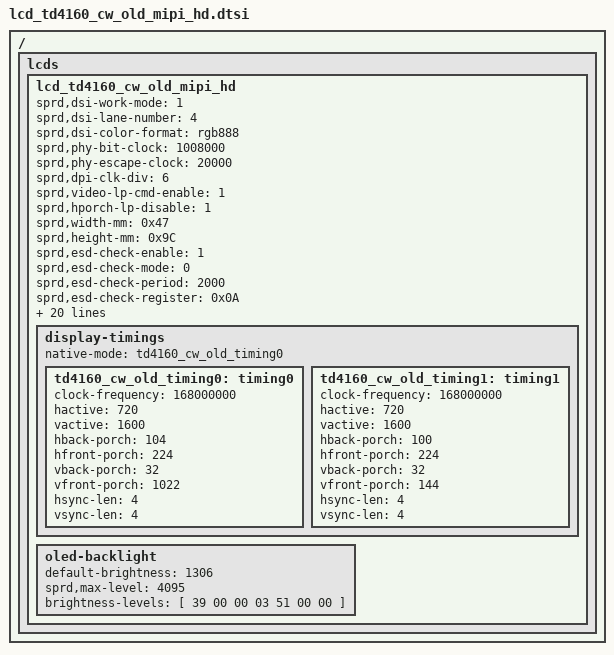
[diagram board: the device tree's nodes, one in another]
/*
 * R61350 Truly LCD config dtsi file for spreadtrum
 *
 * Copyright (C) 2018, Spreadtrum Communications Inc.
 *
 * SPDX-License-Identifier: (GPL-2.0+ OR MIT)
 */

/ {
	fragment {
		target-path = "/";
		__overlay__ {
			lcds {
				lcd_td4160_cw_old_mipi_hd: lcd_td4160_cw_old_mipi_hd {

					sprd,dsi-work-mode = <1>; /* video burst mode*/
					sprd,dsi-lane-number = <4>;
					sprd,dsi-color-format = "rgb888";

					sprd,phy-bit-clock = <1008000>;	/* kbps */
					sprd,phy-escape-clock = <20000>;/* kHz */
					sprd,dpi-clk-div = <6>;
					sprd,video-lp-cmd-enable = <1>;
					sprd,hporch-lp-disable = <1>;

					sprd,width-mm = <0x47>;
					sprd,height-mm = <0x9C>;

					sprd,esd-check-enable = <1>;
					sprd,esd-check-mode = <0>;
					sprd,esd-check-period = <2000>;
					sprd,esd-check-register = <0x0A>;
					sprd,esd-check-value = <0x9C>;

					sprd,power-i2c-bus = <4>;
					sprd,power-i2c-addr = <0x3e>;
					sprd,power-i2c-reg = [00 01 03];
					sprd,power-i2c-val = [14 14 43];

					sprd,reset-on-sequence = <1 5>, <0 5>, <1 30>;
					sprd,reset-off-sequence = <0 5>;

					/*
					 * Use 4 bits number for descripting video lp mode, and it can be combined used.
					 * BIT(0): allow vactive enter lp;
					 * BIT(1): allow vfp enter lp;
					 * BIT(2): allow vbp enter lp;
					 * BIT(3): allow vsa enter lp;
					 * For example:
					 * If we need vfp & vbp enter lp, we can calculate this value as a result of BIT(1) | BIT(2)
					 * And we get the result of 3 and set this value to lcd dt property sprd,video-lp-en-mode.
					 * If we need all stage can enter lp, we can calculate this value as a result of BIT(0) | BIT(1) | BIT(2) | BIT(3).
					 * And we get the result of 15 and set this value to lcd dt property sprd,video-lp-en-mode.
					 */
					sprd,video-lp-en-mode = <2>;
					sprd,use-dcs-write;
					sprd,initial-command = [
						39 00 00 02 B0 04
						39 00 00 02 D6 00
						39 00 00 07 B6 30 6A 00 86 C3 03
						39 00 00 05 B7 31 00 00 00
						39 00 00 07 B8 02 50 09 00 04 40
						39 00 00 07 B9 02 09 18 00 09 46
						39 00 00 07 BA 02 90 00 00 00 00
						39 00 00 04 BB 00 B4 A0
						39 00 00 04 BC 00 B4 A0
						39 00 00 04 BD 00 B4 A0
						39 00 00 0E BE 07 00 00 00 00 00 00 00 00 00 00 00 00
						39 00 00 19 C0 00 60 24 06 40 00 16 06 98 00 70 00 00 00 00 00 00 00 00 00 00 00 00 00
						39 00 00 28 C1 30 81 50 FA 01 00 00 10 00 00 00 00 40 0F 00 00 00 00 00 00 00 00 00 00 00 00 00 00 00 00 00 00 F0 07 08 07 D0 0A BE
						39 00 00 65 C2 01 20 50 14 04 10 0B 10 00 00 00 00 00 00 00 00 00 00 00 00 00 00 00 00 00 00 00 00 00 00 00 00 00 00 00 00 00 00 00 00 00 00 05 F0 54 08 08 05 05 C5 00 80 00 00 00 00 08 00 00 00 00 11 00 80 00 08 00 00 00 00 00 00 00 00 00 00 00 00 00 00 00 00 00 00 00 00 00 00 00 00 00 00 00 11 00 00 00 00 00 00
						39 00 00 65 C3 01 00 55 01 01 86 68 00 00 00 20 01 01 00 55 01 01 86 68 00 00 00 20 02 01 00 55 01 01 86 68 00 00 00 20 00 01 00 55 01 01 86 68 00 00 00 20 00 00 00 00 08 00 00 00 00 00 00 00 00 00 00 00 00 00 00 00 00 00 00 00 00 00 00 00 00 00 00 00 00 00 00 00 00 00 00 00 00 00 00 00 00 00 00 00 00 00 00 00 00
						39 00 00 55 C4 00 00 5E 64 00 03 05 13 15 17 19 5D 5F 00 00 00 00 00 00 00 00 00 00 00 00 00 00 00 00 00 00 00 00 5F 5D 1A 18 16 14 06 04 00 64 5E 00 00 00 00 00 00 00 C0 03 00 00 3C 00 00 00 00 00 00 00 00 00 00 00 00 00 57 57 00 00 57 55 55 FF FF FF FF FF 55 55 D5
						39 00 00 06 C5 08 00 00 00 00
						39 00 00 4D C6 00 00 00 00 01 22 04 22 01 00 61 00 00 00 01 00 61 00 01 05 01 0B 01 35 FF 8F 06 C5 02 C0 0F 00 00 00 00 00 00 00 00 00 00 00 00 00 00 00 00 00 00 00 00 00 00 20 20 00 00 00 C0 11 00 00 00 10 10 00 00 00 01 00 50 00 33 03 00 00
						39 00 00 1F CB 02 D0 01 80 00 00 00 00 00 00 00 00 00 00 00 00 00 00 00 00 00 00 40 70 00 00 00 00 00 FF
						39 00 00 19 CE 16 56 66 88 9b aa bb c0 c8 Cd d2 D8 e1 E7 EC F0 F3 07 0F 00 00 00 04 8C
						39 00 00 02 CF 00
						39 00 00 15 D0 C1 46 81 66 09 90 00 CC F2 FF 11 46 06 7E 09 08 CC 1B F0 06
						39 00 00 26 D1 CE D8 1B 33 33 17 07 BB 22 52 22 52 00 3B 77 07 3B 30 06 72 33 13 00 D7 0C 22 02 00 18 70 18 77 11 11 11 20 20
						39 00 00 04 D2 00 00 00
						39 00 00 65 D3 00 00 00 00 00 00 00 00 00 FF F7 FF FF F7 FF FF F7 FF FF F7 FF FF F7 FF FF F7 FF FF F7 FF FF F7 FF FF F7 FF FF F7 FF FF F7 FF FF F7 FF FF F7 FF FF F7 FF FF F7 FF FF F7 FF FF F7 FF FF F7 FF FF F7 FF FF F7 FF FF F7 FF FF F7 FF FF F7 FF FF F7 FF FF F7 FF FF F7 FF FF F7 FF FF F7 FF FF F7 FF FF F7 FF FF
						39 00 00 18 D4 00 00 00 00 00 00 00 00 00 20 00 00 00 00 20 00 00 00 00 00 00 00 00
						39 00 00 02 D6 00
						39 00 00 2F D7 01 00 12 12 00 62 00 16 00 62 00 16 03 83 80 85 85 85 87 84 45 86 87 80 88 86 89 83 83 87 84 88 8A 0C 0B 0A 0A 0A 07 07 06 06 00 08 0A 0A
						39 00 00 17 D8 40 99 26 ED 16 6C 16 6C 16 6C 00 14 00 14 00 14 01 0C 00 00 01 00
						39 00 00 29 D9 00 02 7F 00 00 00 00 00 00 00 00 00 00 00 00 C0 00 00 00 00 00 00 00 00 00 00 00 00 00 00 00 00 00 00 00 00 00 00 00 00
						39 00 00 05 DD 30 06 23 65
						39 00 00 0F DE 00 00 00 0F FF 00 00 00 00 10 00 00 00 00
						39 00 00 05 E5 03 00 00 00
						39 00 00 09 E6 00 00 00 00 00 0E 00 00
						39 00 00 24 EA 02 07 07 04 80 10 01 00 00 00 00 03 23 00 07 00 ED 00 ED 00 ED 01 28 01 28 00 62 00 62 00 62 01 0F 01 00
						39 00 00 09 EB 06 E0 6E 07 61 01 01 00
						39 00 00 18 EC 02 D0 01 70 73 10 01 00 00 00 00 02 2A 00 00 00 00 00 00 00 00 00 00
						39 00 00 22 ED 01 02 00 00 00 00 00 00 67 A6 F0 00 00 00 00 00 00 00 00 00 00 00 00 F0 01 00 00 00 00 00 41 10 01
						39 00 00 65 EE 05 00 05 00 C0 0B 00 00 03 00 00 03 00 00 03 00 C0 03 00 00 00 00 00 00 03 00 00 00 00 00 00 03 00 00 00 00 00 00 03 00 00 00 00 00 00 03 00 40 03 04 65 40 00 00 55 17 04 65 40 00 00 55 03 04 65 40 00 00 40 17 04 65 40 00 00 00 03 00 00 03 00 00 03 00 00 03 00 00 03 00 00 03 00 00 03 00 40 15 00 00
						39 00 00 0C F9 20 3F E0 00 00 07 FF 00 00 07 FF
						39 00 00 02 35 00
						39 00 00 4D C7 00 00 00 72 00 B9 00 D4 00 ED 00 F8 01 08 01 0C 01 2C 00 FE 01 57 01 1D 01 63 01 22 01 92 01 9E 02 27 02 92 02 A0 00 00 00 72 00 B9 00 D4 00 ED 00 F8 01 08 01 0C 01 2C 00 FE 01 57 01 1D 01 63 01 22 01 92 01 9E 02 27 02 92 02 A0
						39 00 00 02 53 24
						39 00 00 02 55 00
						39 00 00 02 B0 03
						05 60 00 01 11
						05 20 00 01 29
						];

					sprd,sleep-in-command = [
						05 14 00 01 28
						05 78 00 01 10
						];

					sprd,sleep-out-command = [
						05 14 00 01 11
						05 78 00 01 29
						];

					sprd,cabc-off-command = [
						39 00 00 02 55 03
						];
					sprd,cabc-ui-command = [
						39 00 00 02 55 01
						];
					sprd,cabc-still-command = [
						39 00 00 02 55 02
						];
					sprd,cabc-moving-command = [
						39 00 00 02 55 03
						];

					display-timings {
						native-mode = <&td4160_cw_old_timing0>;

						td4160_cw_old_timing0: timing0 {
							clock-frequency = <168000000>;
							hactive = <720>;
							vactive = <1600>;
							hback-porch = <104>;
							hfront-porch = <224>;
							vback-porch = <32>;
							vfront-porch = <1022>;
							hsync-len = <4>;
							vsync-len = <4>;
						};

						td4160_cw_old_timing1: timing1 {
							clock-frequency = <168000000>;
							hactive = <720>;
							vactive = <1600>;
							hback-porch = <100>;
							hfront-porch = <224>;
							vback-porch = <32>;
							vfront-porch = <144>;
							hsync-len = <4>;
							vsync-len = <4>;
						};
					};
					oled-backlight {
						default-brightness = <1306>;
						sprd,max-level = <4095>;
						brightness-levels = [
							39 00 00 03 51 00 00
						];
					};
				};
			};
		};
	};
};
